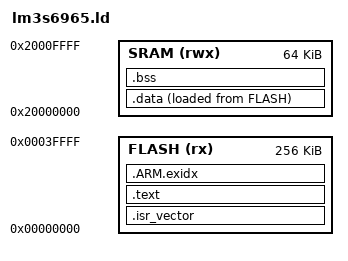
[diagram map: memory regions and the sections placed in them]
/* Linker script for TI Stellaris LM3S6965 (QEMU machine lm3s6965evb):
 * 256 KiB flash at 0x00000000, 64 KiB SRAM at 0x20000000. */
ENTRY(Reset_Handler)

MEMORY
{
    FLASH (rx)  : ORIGIN = 0x00000000, LENGTH = 256K
    SRAM  (rwx) : ORIGIN = 0x20000000, LENGTH = 64K
}

_estack = ORIGIN(SRAM) + LENGTH(SRAM);
_min_stack = 0x1000;

SECTIONS
{
    .isr_vector : { KEEP(*(.isr_vector)) } > FLASH

    .text : {
        *(.text*)
        *(.rodata*)
        . = ALIGN(4);
    } > FLASH

    .ARM.exidx : { *(.ARM.exidx*) } > FLASH

    _sidata = LOADADDR(.data);
    .data : {
        . = ALIGN(4);
        _sdata = .;
        *(.data*)
        . = ALIGN(4);
        _edata = .;
    } > SRAM AT > FLASH

    .bss (NOLOAD) : {
        . = ALIGN(4);
        _sbss = .;
        *(.bss*)
        *(COMMON)
        . = ALIGN(4);
        _ebss = .;
    } > SRAM

    ASSERT(_ebss + _min_stack <= _estack, "RAM overflow: .bss leaves < 4 KiB stack")
}
